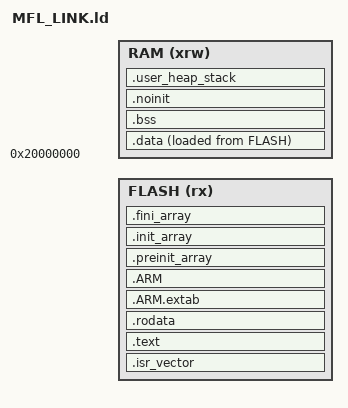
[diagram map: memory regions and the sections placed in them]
ENTRY(Reset_Handler)

_estack = ORIGIN(RAM) + LENGTH(RAM);
_Min_Heap_Size = 0x200;      /* required amount of heap  */
_Min_Stack_Size = 0x400;     /* required amount of stack */

/* memory map */
MEMORY {
  FLASH (rx) : ORIGIN = 0x08000000 + LD_FLASH_OFFSET, LENGTH = LD_MAX_SIZE - LD_FLASH_OFFSET
  RAM (xrw) : ORIGIN = 0x20000000, LENGTH = LD_MAX_DATA_SIZE
}

SECTIONS {
  /* ISR vectors */
  /* The startup code into "FLASH" Rom type memory */
  .isr_vector : {
    . = ALIGN(4);
    KEEP(*(.isr_vector)) /* Startup code */
    . = ALIGN(4);
  } >FLASH AT> FLASH

  /* The program code and other data into "FLASH" Rom type memory */
  .text : {
    . = ALIGN(4);
    *(.text)
    *(.text*)
    *(.glue_7)
    *(.glue_7t)
    *(.eh_frame)
    KEEP (*(.init))
    KEEP (*(.fini))
    . = ALIGN(4);
    _etext = .;     /* define a global symbols at end of code */
  } >FLASH AT> FLASH

  /* Constant data into "FLASH" Rom type memory */
  .rodata (READONLY) : {
    . = ALIGN(4);
    *(.rodata)
    *(.rodata*)
    . = ALIGN(4);
  } >FLASH

  .ARM.extab (READONLY) : {
    . = ALIGN(4);
    *(.ARM.extab* .gnu.linkonce.armextab.*)
    . = ALIGN(4);
  } >FLASH

  .ARM (READONLY) : {
    . = ALIGN(4);
    __exidx_start = .;
    *(.ARM.exidx*)
    __exidx_end = .;
    . = ALIGN(4);
  } >FLASH

  .preinit_array (READONLY) : {
    . = ALIGN(4);
    PROVIDE_HIDDEN(__preinit_array_start = .);
    KEEP (*(.preinit_array*))
    PROVIDE_HIDDEN(__preinit_array_end = .);
    . = ALIGN(4);
  } >FLASH

  .init_array (READONLY) : {
    . = ALIGN(4);
    PROVIDE_HIDDEN(__init_array_start = .);
    KEEP (*(SORT(.init_array.*)))
    KEEP (*(.init_array*))
    PROVIDE_HIDDEN(__init_array_end = .);
    . = ALIGN(4);
  } >FLASH

  .fini_array (READONLY) : {
    . = ALIGN(4);
    PROVIDE_HIDDEN(__fini_array_start = .);
    KEEP (*(SORT(.fini_array.*)))
    KEEP (*(.fini_array*))
    PROVIDE_HIDDEN(__fini_array_end = .);
    . = ALIGN(4);
  } >FLASH

  .data : {
    . = ALIGN(4);
    _sdata = .;
    *(.data)            /* .data sections read/write initialized data */
    *(.data*)
    . = ALIGN(4);
    _edata = .;
  } >RAM AT >FLASH

  _sidata = LOADADDR(.data);

  . = ALIGN(4);
  .bss : {              /* zero initialized bss section */
    _sbss = .;
    __bss_start__ = _sbss;
    *(.bss)
    *(.bss*)
    *(COMMON)
    . = ALIGN(4);
    _ebss = .;
    __bss_end__ = _ebss;
  } >RAM

  .noinit (NOLOAD) : {
    . = ALIGN(4);
    _snoinit = .;
    *(.noinit)
    *(.noinit*)
    . = ALIGN(4);
    _enoinit = .;
  } >RAM

  .user_heap_stack : {
    . = ALIGN(8);
    PROVIDE ( end = . );
    PROVIDE ( _end = . );
    . = . + _Min_Heap_Size;
    . = . + _Min_Stack_Size;
    . = ALIGN(8);
  } >RAM

  /* Remove information from the compiler libraries */
  /DISCARD/ : {
    libc.a ( * )
    libm.a ( * )
    libgcc.a ( * )
  }

  .ARM.attributes 0 : { *(.ARM.attributes) }
}
